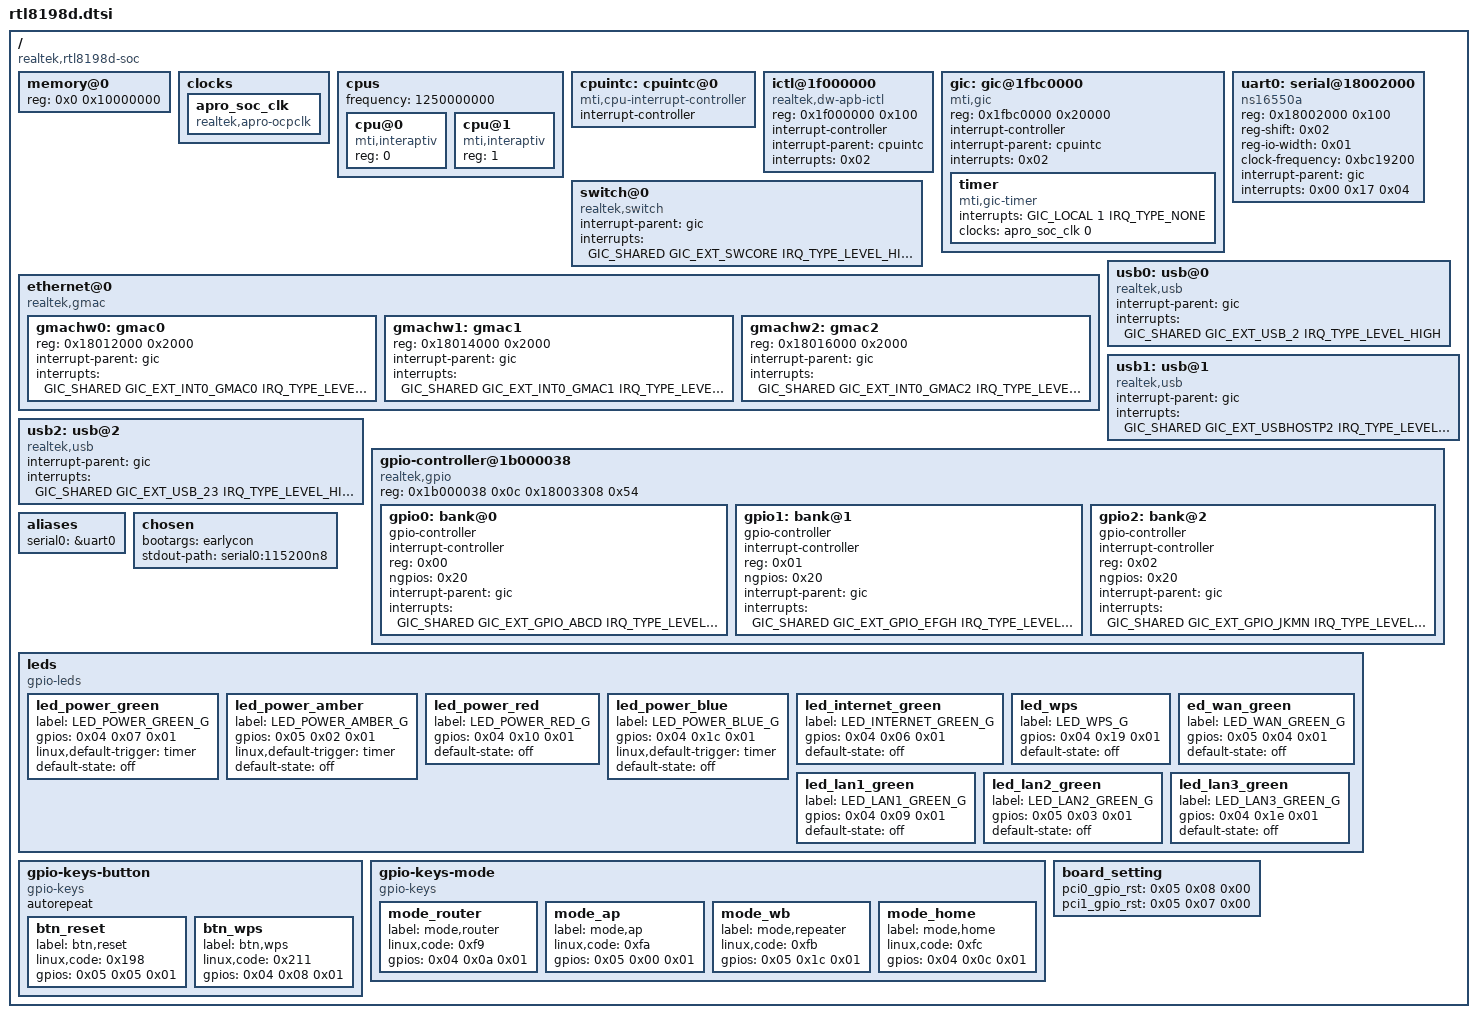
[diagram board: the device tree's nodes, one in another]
// SPDX-License-Identifier: GPL-2.0-or-later

#include <dt-bindings/interrupt-controller/mips-gic.h>

#define GIC_EXT_SWCORE 0x0f
#define GIC_EXT_INT0_GMAC0 0x24
#define GIC_EXT_INT0_GMAC1 0x26
#define GIC_EXT_INT0_GMAC2 0x28
#define GIC_EXT_USB_2 0x33
#define GIC_EXT_USBHOSTP2 0x11
#define GIC_EXT_USB_23 0x34
#define GIC_EXT_GPIO_ABCD 0x15
#define GIC_EXT_GPIO_EFGH 0x16
#define GIC_EXT_GPIO_JKMN 0x12

/dts-v1/;

/ {
	compatible = "realtek,rtl8198d-soc";
	#address-cells = <0x01>;
	#size-cells = <0x01>;
 
 	memory@0 {
		device_type = "memory";
		reg = <0x0 0x10000000>;
	};

	clocks {
 
		apro_soc_clk: apro_soc_clk {
			compatible = "realtek,apro-ocpclk";
			#clock-cells = <0x01>;
		};
	};
 
	cpus {
		#address-cells = <0x01>;
		#size-cells = <0x00>;
		frequency = <1250000000>;
 
		cpu@0 {
			compatible = "mti,interaptiv";
			device_type = "cpu";
			reg = <0>;
		};

		cpu@1 {
			compatible = "mti,interaptiv";
			device_type = "cpu";
			reg = <1>;
		};
	};
 
	cpuintc: cpuintc@0 {
		#address-cells = <0x00>;
		#interrupt-cells = <0x01>;
		interrupt-controller;
		compatible = "mti,cpu-interrupt-controller";
	};
 
	ictl@1f000000 {
		compatible = "realtek,dw-apb-ictl";
		reg = <0x1f000000 0x100>;
		interrupt-controller;
		#interrupt-cells = <0x01>;
		interrupt-parent = <&cpuintc>;
		interrupts = <0x02>;
	};
 
	gic: gic@1fbc0000 {
		compatible = "mti,gic";
		reg = <0x1fbc0000 0x20000>;
		interrupt-controller;
		#interrupt-cells = <0x03>;
		interrupt-parent = <&cpuintc>;
		interrupts = <0x02>;
 
		timer {
			compatible = "mti,gic-timer";
			interrupts = <GIC_LOCAL 1 IRQ_TYPE_NONE>;
			clocks = <&apro_soc_clk 0>;
		};
	};
 
	uart0: serial@18002000 {
		compatible = "ns16550a";
		reg = <0x18002000 0x100>;
		reg-shift = <0x02>;
		reg-io-width = <0x01>;
		clock-frequency = <0xbc19200>;
		interrupt-parent = <&gic>;
		interrupts = <0x00 0x17 0x04>;
	};

	switch@0 {
		compatible = "realtek,switch";
		interrupt-parent = <&gic>;
		interrupts = <GIC_SHARED GIC_EXT_SWCORE IRQ_TYPE_LEVEL_HIGH>;
	};
 
	ethernet@0 {
		compatible = "realtek,gmac";
 
		gmachw0: gmac0 {
			reg = <0x18012000 0x2000>;
			interrupt-parent = <&gic>;
			interrupts = <GIC_SHARED GIC_EXT_INT0_GMAC0 IRQ_TYPE_LEVEL_HIGH>;
		};
 
		gmachw1: gmac1 {
			reg = <0x18014000 0x2000>;
			interrupt-parent = <&gic>;
			interrupts = <GIC_SHARED GIC_EXT_INT0_GMAC1 IRQ_TYPE_LEVEL_HIGH>;
		};
 
		gmachw2: gmac2 {
			reg = <0x18016000 0x2000>;
			interrupt-parent = <&gic>;
			interrupts = <GIC_SHARED GIC_EXT_INT0_GMAC2 IRQ_TYPE_LEVEL_HIGH>;
		};
	};
 
	usb0: usb@0 {
		compatible = "realtek,usb";
		interrupt-parent = <&gic>;
		interrupts = <GIC_SHARED GIC_EXT_USB_2 IRQ_TYPE_LEVEL_HIGH>;
	};
 
	usb1: usb@1 {
		compatible = "realtek,usb";
		interrupt-parent = <&gic>;
		interrupts = <GIC_SHARED GIC_EXT_USBHOSTP2 IRQ_TYPE_LEVEL_HIGH>;
	};
 
	usb2: usb@2 {
		compatible = "realtek,usb";
		interrupt-parent = <&gic>;
		interrupts = <GIC_SHARED GIC_EXT_USB_23 IRQ_TYPE_LEVEL_HIGH>;
	};
 
	gpio-controller@1b000038 {
		#address-cells = <0x01>;
		#size-cells = <0x00>;
		compatible = "realtek,gpio";
		reg = <0x1b000038 0x0c 0x18003308 0x54>;
 
		gpio0: bank@0 {
			gpio-controller;
			interrupt-controller;
			reg = <0x00>;
			ngpios = <0x20>;
			#gpio-cells = <0x02>;
			#interrupt-cells = <0x02>;
			interrupt-parent = <&gic>;
			interrupts = <GIC_SHARED GIC_EXT_GPIO_ABCD IRQ_TYPE_LEVEL_HIGH>;
		};
 
		gpio1: bank@1 {
			gpio-controller;
			interrupt-controller;
			reg = <0x01>;
			ngpios = <0x20>;
			#gpio-cells = <0x02>;
			#interrupt-cells = <0x02>;
			interrupt-parent = <&gic>;
			interrupts = <GIC_SHARED GIC_EXT_GPIO_EFGH IRQ_TYPE_LEVEL_HIGH>;
		};
 
		gpio2: bank@2 {
			gpio-controller;
			interrupt-controller;
			reg = <0x02>;
			ngpios = <0x20>;
			#gpio-cells = <0x02>;
			#interrupt-cells = <0x02>;
			interrupt-parent = <&gic>;
			interrupts = <GIC_SHARED GIC_EXT_GPIO_JKMN IRQ_TYPE_LEVEL_HIGH>;
		};
	};
 
	aliases {
		serial0 = &uart0;
	};

	chosen {
		bootargs = "earlycon";
		stdout-path = "serial0:115200n8";
	};
 
	leds {
		compatible = "gpio-leds";
 
		led_power_green {
			label = "LED_POWER_GREEN_G";
			gpios = <0x04 0x07 0x01>;
			linux,default-trigger = "timer";
			default-state = "off";
		};
 
		led_power_amber {
			label = "LED_POWER_AMBER_G";
			gpios = <0x05 0x02 0x01>;
			linux,default-trigger = "timer";
			default-state = "off";
		};
 
		led_power_red {
			label = "LED_POWER_RED_G";
			gpios = <0x04 0x10 0x01>;
			default-state = "off";
		};
 
		led_power_blue {
			label = "LED_POWER_BLUE_G";
			gpios = <0x04 0x1c 0x01>;
			linux,default-trigger = "timer";
			default-state = "off";
		};
 
		led_internet_green {
			label = "LED_INTERNET_GREEN_G";
			gpios = <0x04 0x06 0x01>;
			default-state = "off";
		};
 
		led_wps {
			label = "LED_WPS_G";
			gpios = <0x04 0x19 0x01>;
			default-state = "off";
		};
 
		ed_wan_green {
			label = "LED_WAN_GREEN_G";
			gpios = <0x05 0x04 0x01>;
			default-state = "off";
		};
 
		led_lan1_green {
			label = "LED_LAN1_GREEN_G";
			gpios = <0x04 0x09 0x01>;
			default-state = "off";
		};
 
		led_lan2_green {
			label = "LED_LAN2_GREEN_G";
			gpios = <0x05 0x03 0x01>;
			default-state = "off";
		};
 
		led_lan3_green {
			label = "LED_LAN3_GREEN_G";
			gpios = <0x04 0x1e 0x01>;
			default-state = "off";
		};
	};
 
	gpio-keys-button {
		compatible = "gpio-keys";
		autorepeat;
 
		btn_reset {
			label = "btn,reset";
			linux,code = <0x198>;
			gpios = <0x05 0x05 0x01>;
		};
 
		btn_wps {
			label = "btn,wps";
			linux,code = <0x211>;
			gpios = <0x04 0x08 0x01>;
		};
	};
 
	gpio-keys-mode {
		compatible = "gpio-keys";
 
		mode_router {
			label = "mode,router";
			linux,code = <0xf9>;
			gpios = <0x04 0x0a 0x01>;
		};
 
		mode_ap {
			label = "mode,ap";
			linux,code = <0xfa>;
			gpios = <0x05 0x00 0x01>;
		};
 
		mode_wb {
			label = "mode,repeater";
			linux,code = <0xfb>;
			gpios = <0x05 0x1c 0x01>;
		};
 
		mode_home {
			label = "mode,home";
			linux,code = <0xfc>;
			gpios = <0x04 0x0c 0x01>;
		};
	};
 
	board_setting {
		pci0_gpio_rst = <0x05 0x08 0x00>;
		pci1_gpio_rst = <0x05 0x07 0x00>;
	};
};
